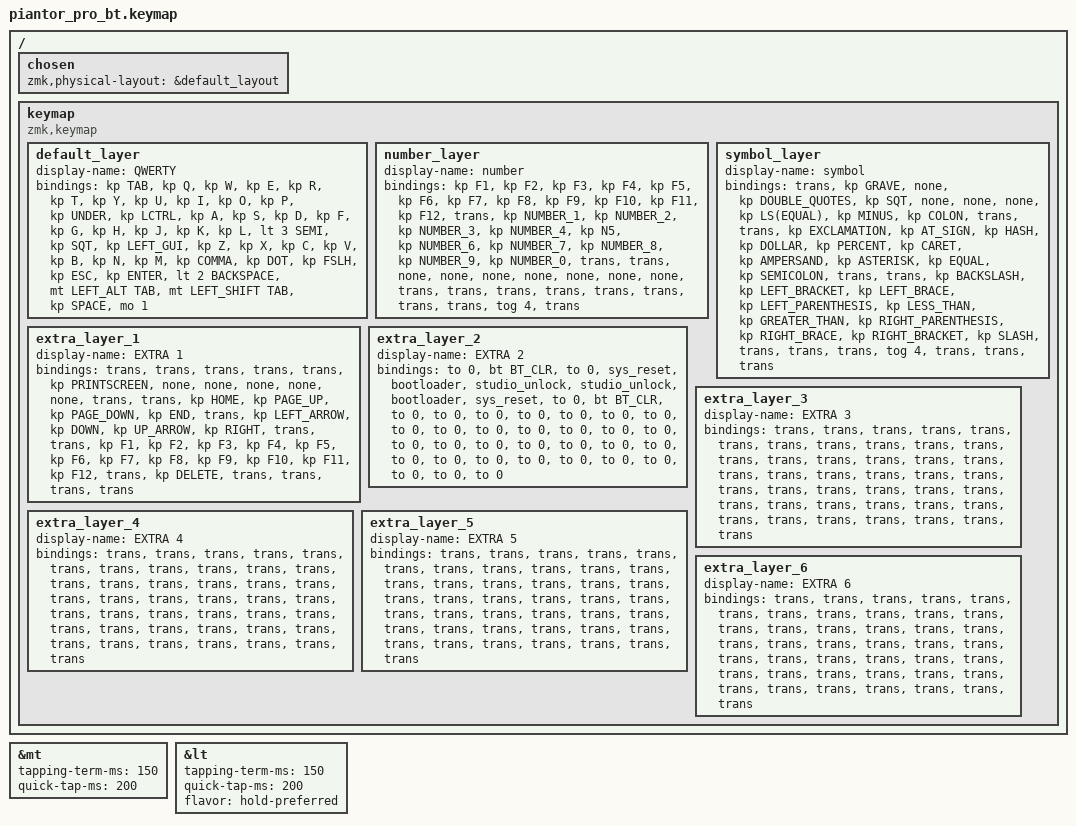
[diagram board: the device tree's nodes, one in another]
/*
 * Copyright (c) 2020 The ZMK Contributors
 *
 * SPDX-License-Identifier: MIT
 */

#include <behaviors.dtsi>
#include <dt-bindings/zmk/bt.h>
#include <dt-bindings/zmk/keys.h>

&mt {
    tapping-term-ms = <150>;
    quick-tap-ms = <200>;
};

&lt {
    tapping-term-ms = <150>;
    quick-tap-ms = <200>;
    flavor = "hold-preferred";
};

/ {
    chosen { zmk,physical-layout = &default_layout; };
};

/ {
    keymap {
        compatible = "zmk,keymap";

        default_layer {
            display-name = "QWERTY";

            // --------------------------------------------------------------------------------
            // |  TAB |  Q  |  W  |  E  |  R  |  T  |  Y  |  U   |  I  |  O  |  P  | BSPC |
            // | CTRL |  A  |  S  |  D  |  F  |  G  |  H  |  J   |  K  |  L  |  ;  |  '   |
            // | SHFT |  Z  |  X  |  C  |  V  |  B  |  N  |  M   |  ,  |  .  |  /  | ESC  |
            //                    | GUI | LWR | SPC | ENT | RSE  | ALT |

            bindings = <
&kp TAB  &kp Q  &kp W  &kp E  &kp R  &kp T  &kp Y  &kp U  &kp I  &kp O  &kp P  &kp UNDER  &kp LCTRL  &kp A  &kp S  &kp D  &kp F  &kp G  &kp H  &kp J  &kp K  &kp L  &lt 3 SEMI  &kp SQT  &kp LEFT_GUI  &kp Z  &kp X  &kp C  &kp V  &kp B  &kp N  &kp M  &kp COMMA  &kp DOT  &kp FSLH  &kp ESC  &kp ENTER  &lt 2 BACKSPACE  &mt LEFT_ALT TAB  &mt LEFT_SHIFT TAB  &kp SPACE  &mo 1
            >;
        };

        number_layer {
            display-name = "number";

            // -----------------------------------------------------------------------------------------
            // |  TAB |  1  |  2  |  3  |  4  |  5    |  6  |  7  |  8  |  9  |  0  | BSPC |
            // | CTRL | BT1 | BT2 | BT3 | BT4 | BT5   | LFT | DWN |  UP | RGT |     |      |
            // | SHFT | BTCR| RGB | RST | BOOT| Unlock|     |     |     |     |     |      |
            //                    | GUI |     | SPC   | ENT |     | ALT |

            bindings = <
&kp F1  &kp F2  &kp F3  &kp F4  &kp F5  &kp F6  &kp F7  &kp F8  &kp F9  &kp F10  &kp F11  &kp F12  &trans  &kp NUMBER_1  &kp NUMBER_2  &kp NUMBER_3  &kp NUMBER_4  &kp N5  &kp NUMBER_6  &kp NUMBER_7  &kp NUMBER_8  &kp NUMBER_9  &kp NUMBER_0  &trans  &trans  &none  &none  &none  &none  &none  &none  &none  &trans  &trans  &trans  &trans  &trans  &trans  &trans  &trans  &tog 4  &trans
            >;
        };

        symbol_layer {
            display-name = "symbol";

            // -----------------------------------------------------------------------------------------
            // |  TAB |  !  |  @  |  #  |  $  |  %  |  ^  |  &  |  *  |  (  |  )  | BSPC |
            // | CTRL |     |     |     |     |     |  -  |  =  |  [  |  ]  |  \  |  `   |
            // | SHFT |     |     |     |     |     |  _  |  +  |  {  |  }  | "|" |  ~   |
            //                    | GUI |     | SPC | ENT |     | ALT |

            bindings = <
&trans  &kp GRAVE  &none  &kp DOUBLE_QUOTES  &kp SQT  &none  &none  &none  &kp LS(EQUAL)  &kp MINUS  &kp COLON  &trans  &trans  &kp EXCLAMATION  &kp AT_SIGN  &kp HASH  &kp DOLLAR  &kp PERCENT  &kp CARET  &kp AMPERSAND  &kp ASTERISK  &kp EQUAL  &kp SEMICOLON  &trans  &trans  &kp BACKSLASH  &kp LEFT_BRACKET  &kp LEFT_BRACE  &kp LEFT_PARENTHESIS  &kp LESS_THAN  &kp GREATER_THAN  &kp RIGHT_PARENTHESIS  &kp RIGHT_BRACE  &kp RIGHT_BRACKET  &kp SLASH  &trans  &trans  &trans  &tog 4  &trans  &trans  &trans
            >;
        };

        extra_layer_1 {
            display-name = "EXTRA 1";
            bindings = <
&trans  &trans  &trans  &trans  &trans  &kp PRINTSCREEN  &none  &none  &none  &none  &none  &trans  &trans  &kp HOME  &kp PAGE_UP  &kp PAGE_DOWN  &kp END  &trans  &kp LEFT_ARROW  &kp DOWN  &kp UP_ARROW  &kp RIGHT  &trans  &trans  &kp F1  &kp F2  &kp F3  &kp F4  &kp F5  &kp F6  &kp F7  &kp F8  &kp F9  &kp F10  &kp F11  &kp F12  &trans  &kp DELETE  &trans  &trans  &trans  &trans
            >;
        };

        extra_layer_2 {
            display-name = "EXTRA 2";
            bindings = <
&to 0  &bt BT_CLR  &to 0  &sys_reset  &bootloader  &studio_unlock  &studio_unlock  &bootloader  &sys_reset  &to 0  &bt BT_CLR  &to 0  &to 0  &to 0  &to 0  &to 0  &to 0  &to 0 &to 0 &to 0 &to 0 &to 0 &to 0  &to 0 &to 0 &to 0 &to 0 &to 0  &to 0 &to 0 &to 0 &to 0 &to 0  &to 0 &to 0 &to 0 &to 0 &to 0 &to 0 &to 0 &to 0 &to 0
            >;
        };

        extra_layer_3 {
            display-name = "EXTRA 3";
            bindings = <
&trans  &trans  &trans  &trans  &trans  &trans  &trans  &trans  &trans  &trans  &trans  &trans  &trans  &trans  &trans  &trans  &trans  &trans  &trans  &trans  &trans  &trans  &trans  &trans  &trans  &trans  &trans  &trans  &trans  &trans  &trans  &trans  &trans  &trans  &trans  &trans  &trans  &trans  &trans  &trans  &trans  &trans
            >;
        };

        extra_layer_4 {
            display-name = "EXTRA 4";
            bindings = <
&trans  &trans  &trans  &trans  &trans  &trans  &trans  &trans  &trans  &trans  &trans  &trans  &trans  &trans  &trans  &trans  &trans  &trans  &trans  &trans  &trans  &trans  &trans  &trans  &trans  &trans  &trans  &trans  &trans  &trans  &trans  &trans  &trans  &trans  &trans  &trans  &trans  &trans  &trans  &trans  &trans  &trans
            >;
        };

        extra_layer_5 {
            display-name = "EXTRA 5";
            bindings = <
&trans  &trans  &trans  &trans  &trans  &trans  &trans  &trans  &trans  &trans  &trans  &trans  &trans  &trans  &trans  &trans  &trans  &trans  &trans  &trans  &trans  &trans  &trans  &trans  &trans  &trans  &trans  &trans  &trans  &trans  &trans  &trans  &trans  &trans  &trans  &trans  &trans  &trans  &trans  &trans  &trans  &trans
            >;
        };

        extra_layer_6 {
            display-name = "EXTRA 6";
            bindings = <
&trans  &trans  &trans  &trans  &trans  &trans  &trans  &trans  &trans  &trans  &trans  &trans  &trans  &trans  &trans  &trans  &trans  &trans  &trans  &trans  &trans  &trans  &trans  &trans  &trans  &trans  &trans  &trans  &trans  &trans  &trans  &trans  &trans  &trans  &trans  &trans  &trans  &trans  &trans  &trans  &trans  &trans
            >;
        };
    };
};
